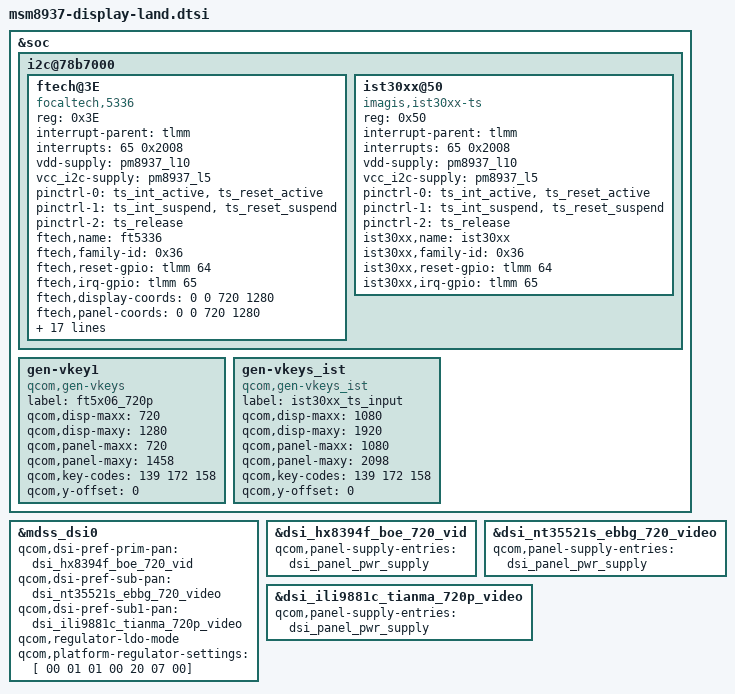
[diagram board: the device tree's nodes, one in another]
/* Copyright (c) 2015-2017, The Linux Foundation. All rights reserved.
 *
 * This program is free software; you can redistribute it and/or modify
 * it under the terms of the GNU General Public License version 2 and
 * only version 2 as published by the Free Software Foundation.
 *
 * This program is distributed in the hope that it will be useful,
 * but WITHOUT ANY WARRANTY; without even the implied warranty of
 * MERCHANTABILITY or FITNESS FOR A PARTICULAR PURPOSE.  See the
 * GNU General Public License for more details.
 */

#include "dsi-panel-hx8394f-boe-720p-video.dtsi"
#include "dsi-panel-nt35521s-ebbg-720p-video.dtsi"
#include "dsi-panel-ili9881c-tianma-720p-video.dtsi"

&soc {
	i2c@78b7000 {
		/delete-node/ synaptics@4b;
		ftech@3E {
			compatible = "focaltech,5336";
			reg = <0x3E>;
			interrupt-parent = <&tlmm>;
			interrupts = <65 0x2008>;
			vdd-supply = <&pm8937_l10>;
			vcc_i2c-supply = <&pm8937_l5>;
			/* pins used by touchscreen */
			pinctrl-names = "pmx_ts_active","pmx_ts_suspend",
				"pmx_ts_release";
			pinctrl-0 = <&ts_int_active &ts_reset_active>;
			pinctrl-1 = <&ts_int_suspend &ts_reset_suspend>;
			pinctrl-2 = <&ts_release>;
			ftech,name = "ft5336";
			ftech,family-id = <0x36>;
			ftech,reset-gpio = <&tlmm 64 0x00>;
			ftech,irq-gpio = <&tlmm 65 0x2008>;
			ftech,display-coords = <0 0 720 1280>;
			ftech,panel-coords = <0 0 720 1280>;
			ftech,virtual-key1 = <139 180 2000>;/*menu*/
			ftech,virtual-key2 = <172 540 2000>;/*home*/
			ftech,virtual-key3 = <158 900 2000>;/*back*/
			ftech,no-force-update;
			ftech,i2c-pull-up;
			ftech,group-id = <1>;
			ftech,hard-reset-delay-ms = <20>;
			ftech,soft-reset-delay-ms = <200>;
			ftech,num-max-touches = <10>;
			ftech,fw-delay-aa-ms = <30>;
			ftech,fw-delay-55-ms = <30>;
			ftech,fw-upgrade-id1 = <0x79>;
			ftech,fw-upgrade-id2 = <0x18>;
			ftech,fw-delay-readid-ms = <10>;
			ftech,fw-delay-era-flsh-ms = <2000>;
			ftech,fw-auto-cal;
			ftech,ignore-id-check;
	};

	ist30xx@50 {
		compatible = "imagis,ist30xx-ts";
		reg = <0x50>;
		interrupt-parent = <&tlmm>;
		interrupts = <65 0x2008>;
		vdd-supply = <&pm8937_l10>;
		vcc_i2c-supply = <&pm8937_l5>;
		/* pins used by touchscreen */
		pinctrl-names = "pmx_ts_active","pmx_ts_suspend",
			"pmx_ts_release";
		pinctrl-0 = <&ts_int_active &ts_reset_active>;
		pinctrl-1 = <&ts_int_suspend &ts_reset_suspend>;
		pinctrl-2 = <&ts_release>;
		ist30xx,name = "ist30xx";
		ist30xx,family-id = <0x36>;
		ist30xx,reset-gpio = <&tlmm 64 0x00>;
		ist30xx,irq-gpio = <&tlmm 65 0x2008>;
		};
	};

	gen-vkey1 {
		compatible = "qcom,gen-vkeys";
		label = "ft5x06_720p";
		qcom,disp-maxx = <720>;
		qcom,disp-maxy = <1280>;
		qcom,panel-maxx = <720>;
		qcom,panel-maxy = <1458>;
		qcom,key-codes = <139 172 158>;
		qcom,y-offset = <0>;
	};

	gen-vkeys_ist {
		compatible = "qcom,gen-vkeys_ist";
		label = "ist30xx_ts_input";
		qcom,disp-maxx = <1080>;
		qcom,disp-maxy = <1920>;
		qcom,panel-maxx = <1080>;
		qcom,panel-maxy = <2098>;
		qcom,key-codes = <139 172 158>;
		qcom,y-offset = <0>;
	};
};

&mdss_dsi0 {
	qcom,dsi-pref-prim-pan = <&dsi_hx8394f_boe_720_vid>;
	qcom,dsi-pref-sub-pan = <&dsi_nt35521s_ebbg_720_video>;
	qcom,dsi-pref-sub1-pan = <&dsi_ili9881c_tianma_720p_video>;

	qcom,regulator-ldo-mode;
	qcom,platform-regulator-settings = [ 00 01 01 00 20 07 00];
};

&dsi_hx8394f_boe_720_vid {
	qcom,panel-supply-entries = <&dsi_panel_pwr_supply>;
};

&dsi_nt35521s_ebbg_720_video {
	qcom,panel-supply-entries = <&dsi_panel_pwr_supply>;
};

&dsi_ili9881c_tianma_720p_video {
	qcom,panel-supply-entries = <&dsi_panel_pwr_supply>;
};
